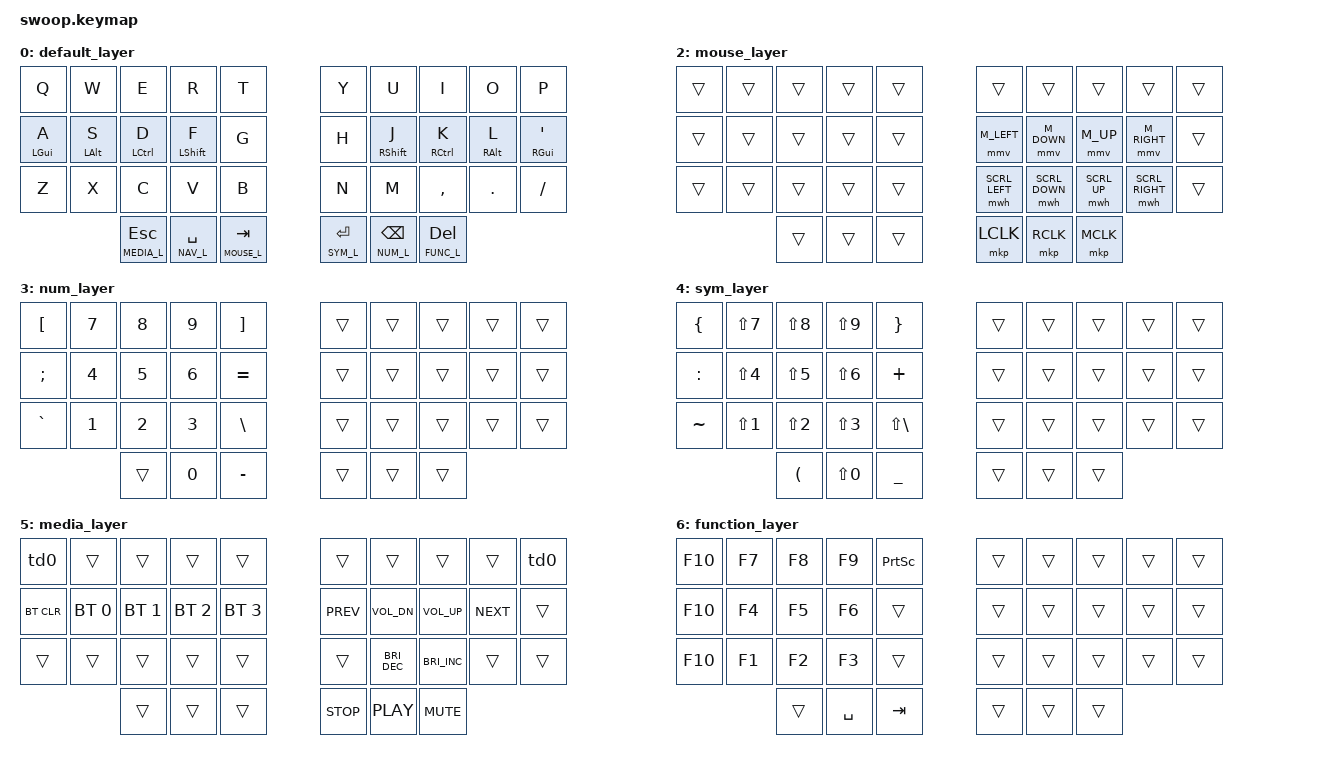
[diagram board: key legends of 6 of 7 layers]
/*
 * Copyright (c) 2020 The ZMK Contributors
 *
 * SPDX-License-Identifier: MIT
 */

#include <behaviors.dtsi>
#include <dt-bindings/zmk/keys.h>
#include <dt-bindings/zmk/bt.h>
#include <dt-bindings/zmk/mouse.h>

#define NAV_L 1
#define MOUSE_L 2
#define NUM_L 3
#define SYM_L 4
#define MEDIA_L 5
#define FUNC_L 6

// Mousekeys definition
#define MOUSE_MAX_SPEED 2400 
#define M_UP MOVE_VERT(-MOUSE_MAX_SPEED)
#define M_DOWN MOVE_VERT(MOUSE_MAX_SPEED)
#define M_LEFT MOVE_HOR(-MOUSE_MAX_SPEED)
#define M_RIGHT MOVE_HOR(MOUSE_MAX_SPEED)

#define U_MOUSE_SCROLL_MAX 80
#define SCRL_UP SCROLL_VERT(U_MOUSE_SCROLL_MAX)
#define SCRL_DOWN SCROLL_VERT(-U_MOUSE_SCROLL_MAX)
#define SCRL_LEFT SCROLL_HOR(-U_MOUSE_SCROLL_MAX)
#define SCRL_RIGHT SCROLL_HOR(U_MOUSE_SCROLL_MAX)

&mmv {
  acceleration-exponent = <1>;
  time-to-max-speed-ms = <1000>;
  delay-ms = <0>;
};

// Using layer taps on thumbs, having quick tap as well helps w/ repeating space/backspace
&lt { 
    tapping_term_ms = <175>; 
    quick_tap_ms = <200>;
};

/ {
    behaviors {
        hm: homerow_mods {
            compatible = "zmk,behavior-hold-tap";
            label = "homerow mods";
            #binding-cells = <2>;
            tapping_term_ms = <200>;
            flavor = "tap-preferred";
            bindings = <&kp>, <&kp>;
        };
        td0: tap_dance_0 {
            compatible = "zmk,behavior-tap-dance";
            label = "TAP_DANCE_0";
            #binding-cells = <0>;
            tapping-term-ms = <200>;
            bindings = <&trans>, <&trans>, <&reset>, <&bootloader>;
        };
    };

    keymap {
        compatible = "zmk,keymap";

        default_layer {
        // +----------------------------------------------.       .-------------------------------------------------
        // |    Q   |   W    |   E    |    R    |   T     |       |    Y   |    U   |    I    |    O    |     P    |
        // +--------+--------+--------+---------+---------|       |--------+--------+---------+---------+----------+
        // |    A   |   S    |   D    |    F    |   G     |       |    H   |    J   |    K    |    L    |     '    |
        // +--------+--------+--------+---------+---------|       |--------+--------+---------+---------+----------+
        // |    Z   |   X    |   C    |    V    |   B     |       |    N   |    M   |    ,    |    .    |     /    |
        // +--------+--------+---------+--------+---------+       |--------+--------+---------+--------------------+
        //                   |   ESC   | SPACE  |  ENTER  |       |  ENTER |  BKSP  |   DEL   |
        //                   '--------+---------+---------'       '--------+--------+---------'
            bindings = <
                &kp Q       &kp W       &kp E            &kp R            &kp T                    &kp Y            &kp U           &kp I        &kp O       &kp P
                &hm LGUI A  &hm LALT S  &hm LCTRL D      &hm LSHFT F      &kp G                    &kp H            &hm RSHFT J     &hm RCTRL K  &hm RALT L  &hm RGUI QUOT
                &kp Z       &kp X       &kp C            &kp V            &kp B                    &kp N            &kp M           &kp COMMA    &kp DOT     &kp FSLH
                                        &lt MEDIA_L ESC  &lt NAV_L SPACE  &lt MOUSE_L TAB          &lt SYM_L ENTER  &lt NUM_L BKSP  &lt FUNC_L DEL
            >;
        };

        nav_layer { // 1
            bindings = <
                &trans     &trans     &trans      &trans     &trans          &trans        &trans         &trans      &trans     &trans
                &trans     &trans     &trans      &trans     &trans          &kp LARW      &kp DARW       &kp UARW    &kp RARW   &caps_word
                &trans     &trans     &trans      &trans     &trans          &kp HOME      &kp PG_DN      &kp PG_UP  &kp END
                                      &trans      &trans     &trans          &kp ENTER     &kp BKSP        &kp DEL
            >;
        };

        mouse_layer { // 2
            bindings = <
                &trans   &trans   &trans   &trans   &trans         &trans           &trans           &trans         &trans            &trans
                &trans   &trans   &trans   &trans   &trans         &mmv M_LEFT      &mmv M_DOWN      &mmv M_UP      &mmv M_RIGHT      &trans
                &trans   &trans   &trans   &trans   &trans         &mwh SCRL_LEFT   &mwh SCRL_DOWN   &mwh SCRL_UP   &mwh SCRL_RIGHT   &trans
                                  &trans   &trans   &trans         &mkp LCLK        &mkp RCLK        &mkp MCLK
            >;
        };

        num_layer { // 3
            bindings = <
                &kp LBKT    &kp N7   &kp N8   &kp N9   &kp RBKT          &trans   &trans   &trans   &trans   &trans
                &kp SEMI    &kp N4   &kp N5   &kp N6   &kp EQUAL         &trans   &trans   &trans   &trans   &trans
                &kp GRAVE   &kp N1   &kp N2   &kp N3   &kp BSLH          &trans   &trans   &trans   &trans   &trans
                                     &trans   &kp N0   &kp MINUS         &trans   &trans   &trans
            >;
        };

        sym_layer { // 4
            bindings = <
                &kp LBRC    &kp LS(N7)   &kp LS(N8)   &kp LS(N9)   &kp RBRC           &trans   &trans   &trans   &trans   &trans
                &kp COLON   &kp LS(N4)   &kp LS(N5)   &kp LS(N6)   &kp PLUS           &trans   &trans   &trans   &trans   &trans
                &kp TILDE   &kp LS(N1)   &kp LS(N2)   &kp LS(N3)   &kp LS(BSLH)       &trans   &trans   &trans   &trans   &trans
                                         &kp LPAR     &kp LS(N0)   &kp UNDER          &trans   &trans   &trans
            >;
        };

        media_layer { // 5
            bindings = <
                &td0        &trans         &trans         &trans         &trans               &trans        &trans          &trans          &trans       &td0
                &bt BT_CLR  &bt BT_SEL 0   &bt BT_SEL 1   &bt BT_SEL 2   &bt BT_SEL 3         &kp C_PREV    &kp C_VOL_DN    &kp C_VOL_UP    &kp C_NEXT   &trans
                &trans      &trans         &trans         &trans         &trans               &trans        &kp C_BRI_DEC   &kp C_BRI_INC   &trans       &trans
                                           &trans         &trans         &trans               &kp C_STOP    &kp C_PLAY      &kp C_MUTE
            >;
        };

        function_layer { // 6
            bindings = <
                &kp F10   &kp F7   &kp F8   &kp F9     &kp PRINTSCREEN       &trans   &trans   &trans   &trans   &trans
                &kp F10   &kp F4   &kp F5   &kp F6     &trans                &trans   &trans   &trans   &trans   &trans
                &kp F10   &kp F1   &kp F2   &kp F3     &trans                &trans   &trans   &trans   &trans   &trans
                                   &trans   &kp SPACE  &kp TAB               &trans   &trans   &trans
            >;
        };
    };
};
